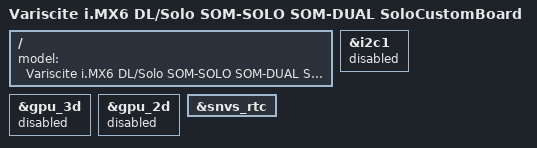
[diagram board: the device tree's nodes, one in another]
/*
 * Copyright (C) 2015-2017 Variscite Ltd.
 *
 * This program is free software; you can redistribute it and/or modify
 * it under the terms of the GNU General Public License version 2 as
 * published by the Free Software Foundation.
 */

#include "imx6dl-var-som-solo.dtsi"
#include "imx6qdl-var-solocb-dt6cb-displays.dtsi"
#include "imx6qdl-var-solocb-buttons.dtsi"
#include "imx6qdl-var-solocb-misc.dtsi"

/ {
	model = "Variscite i.MX6 DL/Solo SOM-SOLO SOM-DUAL SoloCustomBoard";
};

/* URBAN disabled it to lower power consumption */
&gpu_3d {
	status = "disabled";
};
/* URBAN disabled it to lower power consumption */
&gpu_2d {
	status = "disabled";
};

/* override SNVS RTC from imx6qdl*/
&snvs_rtc {
	status = "okay";
};

&i2c1 {
	status = "disabled";
};
